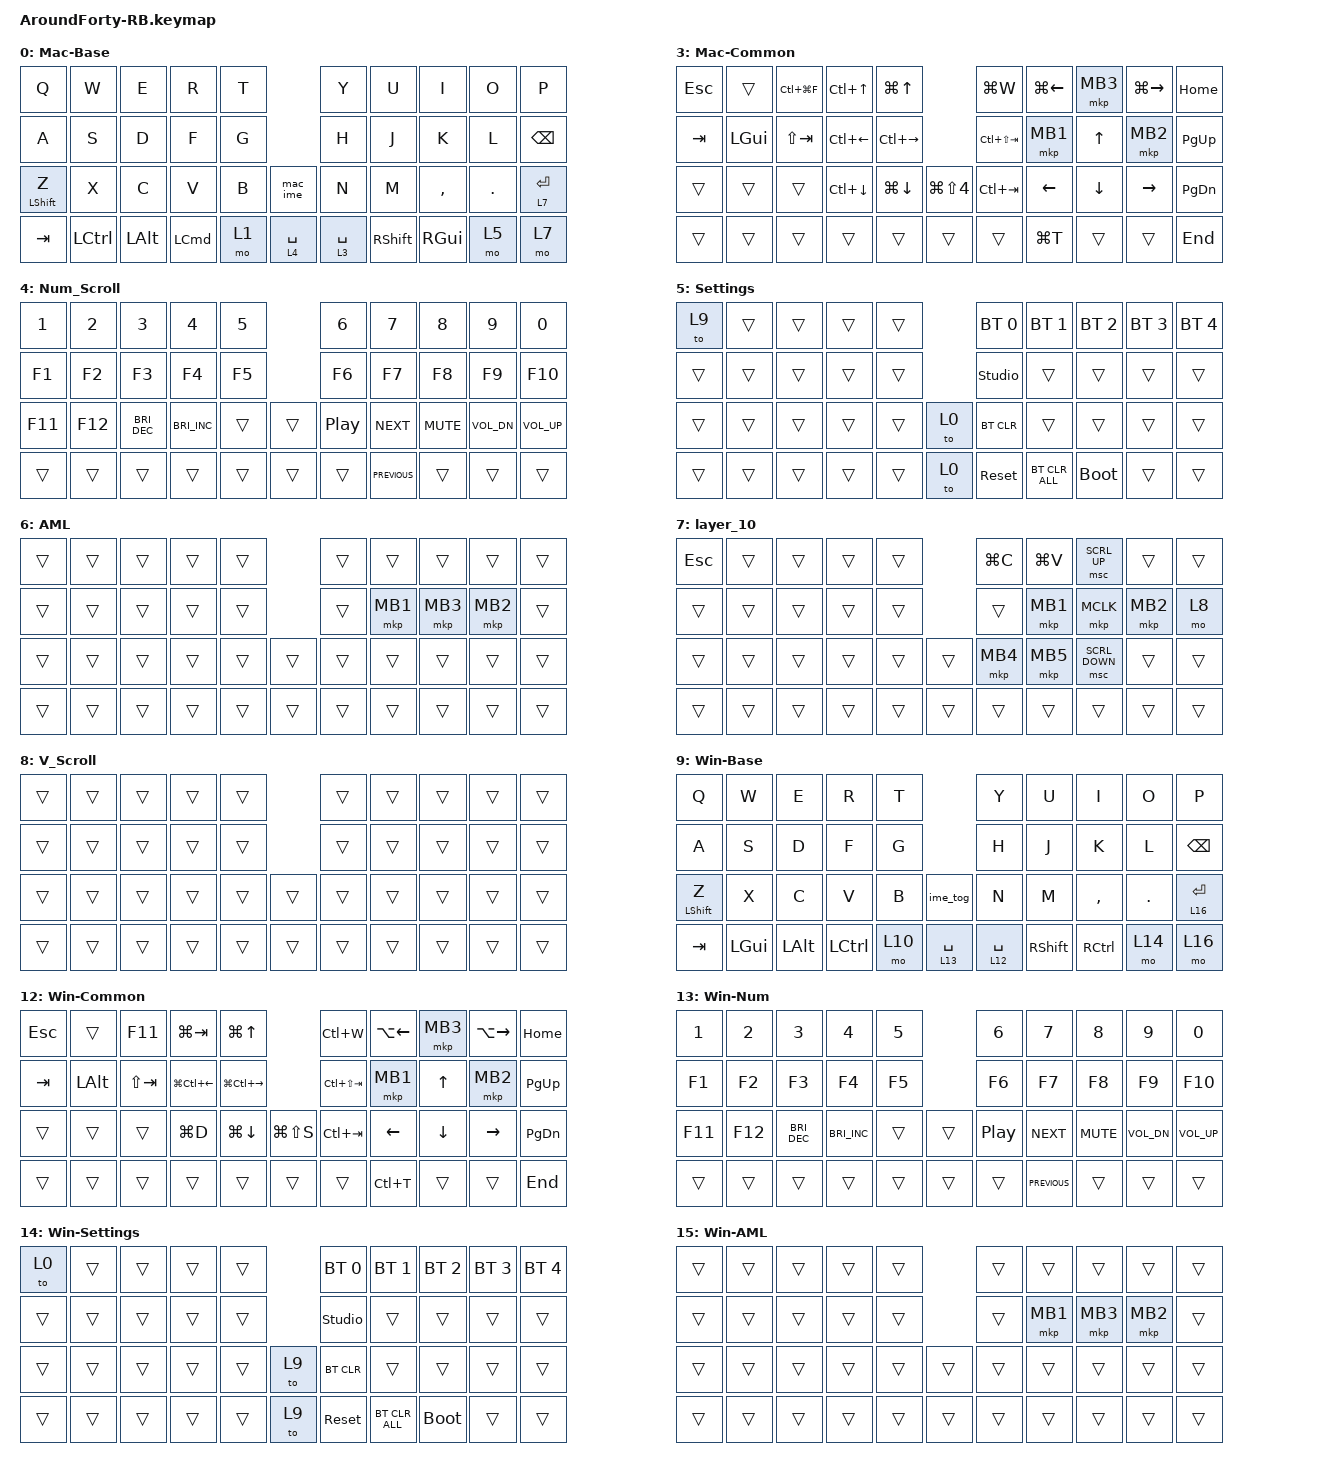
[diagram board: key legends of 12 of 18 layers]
#include <behaviors/rgbled_widget.dtsi>
#include <behaviors.dtsi>
#include <dt-bindings/zmk/bt.h>
#include <dt-bindings/zmk/keys.h>
#include <dt-bindings/zmk/pointing.h>

&mt {
    flavor = "balanced";
    quick-tap-ms = <0>;
};

/ {
    combos {
        compatible = "zmk,combos";

        Escape {
            bindings = <&kp ESCAPE>;
            key-positions = <0 1>;
        };
    };

    macros {
        to_layer_0: to_layer_0 {
            compatible = "zmk,behavior-macro-one-param";
            #binding-cells = <1>;
            bindings = <&to 0 &macro_param_1to1 &kp MACRO_PLACEHOLDER>;
            label = "TO_LAYER_0";
        };

        // Windows用入力切り替え：Alt + Grave (~)

        ime_tog: ime_toggle {
            compatible = "zmk,behavior-macro";
            #binding-cells = <0>;
            bindings =
                <&macro_press>,
                <&kp LALT>,
                <&macro_tap>,
                <&kp GRAVE>,
                <&macro_release>,
                <&kp LALT>;
        };

        // macOS用入力切り替え：Ctrl + Space

        mac_ime: mac_ime_toggle {
            compatible = "zmk,behavior-macro";
            #binding-cells = <0>;
            bindings =
                <&macro_press>,
                <&kp LCTRL>,
                <&macro_tap>,
                <&kp SPACE>,
                <&macro_release>,
                <&kp LCTRL>;
        };
    };

    behaviors {
        lt_to_layer_0: lt_to_layer_0 {
            compatible = "zmk,behavior-hold-tap";
            label = "LAYER_TAP_TO_0";
            bindings = <&mo>, <&to_layer_0>;

            #binding-cells = <2>;
            tapping-term-ms = <200>;
        };
    };

    keymap {
        compatible = "zmk,keymap";

        Mac-Base {
            display-name = "Mac-Base";
            bindings = <
&kp Q             &kp W             &kp E         &kp R     &kp T               &kp Y        &kp U            &kp I          &kp O    &kp P
&kp A             &kp S             &kp D         &kp F     &kp G               &kp H        &kp J            &kp K          &kp L    &kp BACKSPACE
&mt LEFT_SHIFT Z  &kp X             &kp C         &kp V     &kp B  &mac_ime     &kp N        &kp M            &kp COMMA      &kp DOT  &lt 7 ENTER
&kp TAB           &kp LEFT_CONTROL  &kp LEFT_ALT  &kp LCMD  &mo 1  &lt 4 SPACE  &lt 3 SPACE  &kp RIGHT_SHIFT  &kp RIGHT_GUI  &mo 5    &mo 7
            >;
        };

        Mac-Fnc {
            display-name = "Mac-Fnc";
            bindings = <
&trans  &kp LG(X)  &kp LG(C)                 &kp LG(V)             &kp LG(F)                        &kp CARET  &kp AMPERSAND  &kp ASTERISK  &kp LEFT_PARENTHESIS  &kp RIGHT_PARENTHESIS
&trans  &trans     &kp LG(RC(LS(NUMBER_4)))  &kp LG(LS(NUMBER_4))  &kp LS(LG(N5))                   &trans     &kp GRAVE      &kp LBKT      &kp RBKT              &kp BACKSLASH
&mo 2   &trans     &kp LG(LS(LC(A)))         &kp LG(LC(LS(Z)))     &kp LG(LS(NUMBER_3))  &kp LG(R)  &trans     &kp MINUS      &kp EQUAL     &kp SEMICOLON         &kp SQT
&trans  &trans     &trans                    &trans                &trans                &trans     &kp COMMA  &trans         &trans        &kp PERIOD            &kp SLASH
            >;
        };

        layer_9 {
            display-name = "Mac-Fnc";
            bindings = <
&kp EXCLAMATION  &kp AT_SIGN  &kp HASH                  &kp DOLLAR            &kp PERCENT                      &kp CARET      &kp AMPERSAND   &kp ASTERISK    &kp LEFT_PARENTHESIS  &kp RIGHT_PARENTHESIS
&trans           &trans       &kp LG(RC(LS(NUMBER_4)))  &kp LG(LS(NUMBER_4))  &kp LS(LG(N5))                   &trans         &kp TILDE       &kp LEFT_BRACE  &kp RIGHT_BRACE       &kp PIPE
&trans           &trans       &kp LG(LS(LC(A)))         &kp LG(LC(LS(Z)))     &kp LG(LS(NUMBER_3))  &kp LG(R)  &trans         &kp UNDERSCORE  &kp PLUS        &kp COLON             &kp DOUBLE_QUOTES
&trans           &trans       &trans                    &trans                &trans                &trans     &kp LESS_THAN  &trans          &trans          &kp GREATER_THAN      &kp QUESTION
            >;
        };

        Mac-Common {
            display-name = "Mac-Common";
            bindings = <
&kp ESC  &trans        &kp LC(LG(F))  &kp LC(UP_ARROW)    &kp LG(UP_ARROW)                           &kp LG(W)        &kp LG(LEFT_ARROW)  &mkp MB3        &kp LG(RIGHT_ARROW)  &kp HOME
&kp TAB  &kp LEFT_GUI  &kp LS(TAB)    &kp LC(LEFT_ARROW)  &kp LC(RIGHT_ARROW)                        &kp LC(LS(TAB))  &mkp MB1            &kp UP_ARROW    &mkp MB2             &kp PAGE_UP
&trans   &trans        &trans         &kp LC(DOWN_ARROW)  &kp LG(DOWN_ARROW)   &kp LG(LS(NUMBER_4))  &kp LC(TAB)      &kp LEFT_ARROW      &kp DOWN_ARROW  &kp RIGHT_ARROW      &kp PAGE_DOWN
&trans   &trans        &trans         &trans              &trans               &trans                &trans           &kp LG(T)           &trans          &trans               &kp END
            >;
        };

        Num_Scroll {
            bindings = <
&kp NUMBER_1  &kp NUMBER_2  &kp NUMBER_3          &kp NUMBER_4          &kp NUMBER_5          &kp NUMBER_6      &kp N7          &kp NUMBER_8  &kp N9        &kp NUMBER_0
&kp F1        &kp F2        &kp F3                &kp F4                &kp F5                &kp F6            &kp F7          &kp F8        &kp F9        &kp F10
&kp F11       &kp F12       &kp C_BRIGHTNESS_DEC  &kp C_BRIGHTNESS_INC  &trans        &trans  &kp C_PLAY_PAUSE  &kp C_NEXT      &kp C_MUTE    &kp C_VOL_DN  &kp C_VOLUME_UP
&trans        &trans        &trans                &trans                &trans        &trans  &trans            &kp C_PREVIOUS  &trans        &trans        &trans
            >;
        };

        Settings {
            display-name = "Settings";
            bindings = <
&to 9  &trans  &trans  &trans  &trans         &bt BT_SEL 0    &bt BT_SEL 1    &bt BT_SEL 2  &bt BT_SEL 3  &bt BT_SEL 4
&trans  &trans  &trans  &trans  &trans         &studio_unlock  &trans          &trans        &trans        &trans
&trans  &trans  &trans  &trans  &trans  &to 0  &bt BT_CLR      &trans          &trans        &trans        &trans
&trans  &trans  &trans  &trans  &trans  &to 0  &sys_reset      &bt BT_CLR_ALL  &bootloader   &trans        &trans
            >;
        };

        AML {
            display-name = "AML";
            bindings = <
&trans  &trans  &trans  &trans  &trans          &trans  &trans    &trans    &trans    &trans
&trans  &trans  &trans  &trans  &trans          &trans  &mkp MB1  &mkp MB3  &mkp MB2  &trans
&trans  &trans  &trans  &trans  &trans  &trans  &trans  &trans    &trans    &trans    &trans
&trans  &trans  &trans  &trans  &trans  &trans  &trans  &trans    &trans    &trans    &trans
            >;
        };

        layer_10 {
            bindings = <
&kp ESCAPE  &trans  &trans  &trans  &trans          &kp LG(C)  &kp LG(V)  &msc SCRL_UP    &trans    &trans
&trans      &trans  &trans  &trans  &trans          &trans     &mkp MB1   &mkp MCLK       &mkp MB2  &mo 8
&trans      &trans  &trans  &trans  &trans  &trans  &mkp MB4   &mkp MB5   &msc SCRL_DOWN  &trans    &trans
&trans      &trans  &trans  &trans  &trans  &trans  &trans     &trans     &trans          &trans    &trans
            >;
        };

        V_Scroll {
            bindings = <
&trans  &trans  &trans  &trans  &trans          &trans  &trans  &trans  &trans  &trans
&trans  &trans  &trans  &trans  &trans          &trans  &trans  &trans  &trans  &trans
&trans  &trans  &trans  &trans  &trans  &trans  &trans  &trans  &trans  &trans  &trans
&trans  &trans  &trans  &trans  &trans  &trans  &trans  &trans  &trans  &trans  &trans
            >;
        };

        // Windows mode: layer IDs 9-17 (US host layout).
        Win-Base {
            display-name = "Win-Base";
            bindings = <
&kp Q             &kp W         &kp E         &kp R             &kp T                 &kp Y         &kp U            &kp I              &kp O    &kp P
&kp A             &kp S         &kp D         &kp F             &kp G                 &kp H         &kp J            &kp K              &kp L    &kp BACKSPACE
&mt LEFT_SHIFT Z  &kp X         &kp C         &kp V             &kp B   &ime_tog      &kp N         &kp M            &kp COMMA          &kp DOT  &lt 16 ENTER
&kp TAB           &kp LEFT_GUI  &kp LEFT_ALT  &kp LEFT_CONTROL  &mo 10  &lt 13 SPACE  &lt 12 SPACE  &kp RIGHT_SHIFT  &kp RIGHT_CONTROL  &mo 14   &mo 16
            >;
        };

        Win-Fnc {
            display-name = "Win-Fnc";
            bindings = <
&trans  &kp LC(X)  &kp LC(C)          &kp LC(V)          &kp LC(F)                       &kp CARET  &kp AMPERSAND  &kp ASTERISK  &kp LEFT_PARENTHESIS  &kp RIGHT_PARENTHESIS
&trans  &trans     &kp LG(LS(S))      &kp LG(LS(S))      &kp LG(LS(S))                   &trans     &kp GRAVE      &kp LBKT      &kp RBKT              &kp BACKSLASH
&mo 11  &trans     &kp LG(LS(LC(A)))  &kp LG(LC(LS(Z)))  &kp LG(PRINTSCREEN)  &kp LC(R)  &trans     &kp MINUS      &kp EQUAL     &kp SEMICOLON         &kp SQT
&trans  &trans     &trans             &trans             &trans               &trans     &kp COMMA  &trans         &trans        &kp PERIOD            &kp SLASH
            >;
        };

        Win-Symbols {
            display-name = "Win-Symbols";
            bindings = <
&kp EXCLAMATION  &kp AT_SIGN  &kp HASH           &kp DOLLAR         &kp PERCENT                     &kp CARET      &kp AMPERSAND   &kp ASTERISK    &kp LEFT_PARENTHESIS  &kp RIGHT_PARENTHESIS
&trans           &trans       &kp LG(LS(S))      &kp LG(LS(S))      &kp LG(LS(S))                   &trans         &kp TILDE       &kp LEFT_BRACE  &kp RIGHT_BRACE       &kp PIPE
&trans           &trans       &kp LG(LS(LC(A)))  &kp LG(LC(LS(Z)))  &kp LG(PRINTSCREEN)  &kp LC(R)  &trans         &kp UNDERSCORE  &kp PLUS        &kp COLON             &kp DOUBLE_QUOTES
&trans           &trans       &trans             &trans             &trans               &trans     &kp LESS_THAN  &trans          &trans          &kp GREATER_THAN      &kp QUESTION
            >;
        };

        Win-Common {
            display-name = "Win-Common";
            bindings = <
&kp ESC  &trans        &kp F11      &kp LG(TAB)             &kp LG(UP_ARROW)                        &kp LC(W)        &kp LA(LEFT_ARROW)  &mkp MB3        &kp LA(RIGHT_ARROW)  &kp HOME
&kp TAB  &kp LEFT_ALT  &kp LS(TAB)  &kp LG(LC(LEFT_ARROW))  &kp LG(LC(RIGHT_ARROW))                 &kp LC(LS(TAB))  &mkp MB1            &kp UP_ARROW    &mkp MB2             &kp PAGE_UP
&trans   &trans        &trans       &kp LG(D)               &kp LG(DOWN_ARROW)       &kp LG(LS(S))  &kp LC(TAB)      &kp LEFT_ARROW      &kp DOWN_ARROW  &kp RIGHT_ARROW      &kp PAGE_DOWN
&trans   &trans        &trans       &trans                  &trans                   &trans         &trans           &kp LC(T)           &trans          &trans               &kp END
            >;
        };

        Win-Num {
            display-name = "Win-Num";
            bindings = <
&kp NUMBER_1  &kp NUMBER_2  &kp NUMBER_3          &kp NUMBER_4          &kp NUMBER_5          &kp NUMBER_6      &kp N7          &kp NUMBER_8  &kp N9        &kp NUMBER_0
&kp F1        &kp F2        &kp F3                &kp F4                &kp F5                &kp F6            &kp F7          &kp F8        &kp F9        &kp F10
&kp F11       &kp F12       &kp C_BRIGHTNESS_DEC  &kp C_BRIGHTNESS_INC  &trans        &trans  &kp C_PLAY_PAUSE  &kp C_NEXT      &kp C_MUTE    &kp C_VOL_DN  &kp C_VOLUME_UP
&trans        &trans        &trans                &trans                &trans        &trans  &trans            &kp C_PREVIOUS  &trans        &trans        &trans
            >;
        };

        Win-Settings {
            display-name = "Win-Settings";
            bindings = <
&to 0   &trans  &trans  &trans  &trans         &bt BT_SEL 0    &bt BT_SEL 1    &bt BT_SEL 2  &bt BT_SEL 3  &bt BT_SEL 4
&trans  &trans  &trans  &trans  &trans         &studio_unlock  &trans          &trans        &trans        &trans
&trans  &trans  &trans  &trans  &trans  &to 9  &bt BT_CLR      &trans          &trans        &trans        &trans
&trans  &trans  &trans  &trans  &trans  &to 9  &sys_reset      &bt BT_CLR_ALL  &bootloader   &trans        &trans
            >;
        };

        Win-AML {
            display-name = "Win-AML";
            bindings = <
&trans  &trans  &trans  &trans  &trans          &trans  &trans    &trans    &trans    &trans
&trans  &trans  &trans  &trans  &trans          &trans  &mkp MB1  &mkp MB3  &mkp MB2  &trans
&trans  &trans  &trans  &trans  &trans  &trans  &trans  &trans    &trans    &trans    &trans
&trans  &trans  &trans  &trans  &trans  &trans  &trans  &trans    &trans    &trans    &trans
            >;
        };

        Win-Mouse {
            display-name = "Win-Mouse";
            bindings = <
&kp ESCAPE  &trans  &trans  &trans  &trans          &kp LC(C)  &kp LC(V)  &msc SCRL_UP    &trans    &trans
&trans      &trans  &trans  &trans  &trans          &trans     &mkp MB1   &mkp MCLK       &mkp MB2  &mo 17
&trans      &trans  &trans  &trans  &trans  &trans  &mkp MB4   &mkp MB5   &msc SCRL_DOWN  &trans    &trans
&trans      &trans  &trans  &trans  &trans  &trans  &trans     &trans     &trans          &trans    &trans
            >;
        };

        Win-Scroll {
            display-name = "Win-Scroll";
            bindings = <
&trans  &trans  &trans  &trans  &trans          &trans  &trans  &trans  &trans  &trans
&trans  &trans  &trans  &trans  &trans          &trans  &trans  &trans  &trans  &trans
&trans  &trans  &trans  &trans  &trans  &trans  &trans  &trans  &trans  &trans  &trans
&trans  &trans  &trans  &trans  &trans  &trans  &trans  &trans  &trans  &trans  &trans
            >;
        };
    };
};
